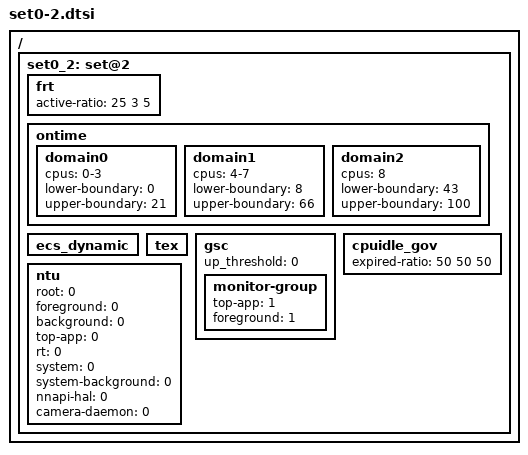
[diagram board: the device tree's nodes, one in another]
/ {
	/* normal mode - app boost */
	set0_2: set@2 {
		frt {	   			/* LIT MED BIG */
			active-ratio 		= < 25   3   5>;
		};

		/* Ontime Migration */
		ontime {
			domain0 {
				cpus = "0-3";
				lower-boundary = <0>;
				upper-boundary = <21>;
			};
			domain1 {
				cpus = "4-7";
				lower-boundary = <8>;
				upper-boundary = <66>;
			};
			domain2 {
				cpus = "8";
				lower-boundary = <43>;
				upper-boundary = <100>;
			};
		};

		ecs_dynamic { };

		tex { };

		gsc {
			up_threshold = <0>;

			monitor-group {
				top-app = <1>;
				foreground = <1>;
			};
		};

		cpuidle_gov {
			expired-ratio = <50 50 50>;
		};

		ntu {
			root			= <0>;
			foreground 		= <0>;
			background		= <0>;
			top-app			= <0>;
			rt			= <0>;
			system			= <0>;
			system-background	= <0>;
			nnapi-hal		= <0>;
			camera-daemon		= <0>;
		};
	};
};
